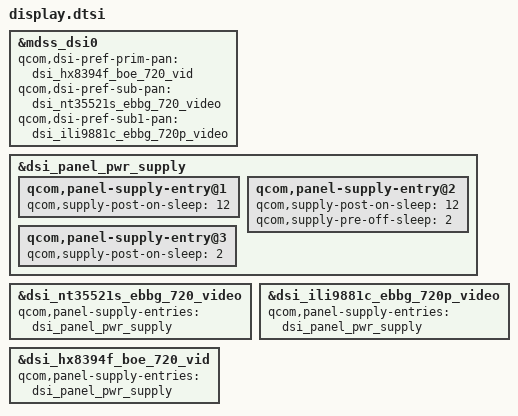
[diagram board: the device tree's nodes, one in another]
#include "panels/dsi-panel-hx8394f-boe-c3a-720p-video.dtsi"
#include "panels/dsi-panel-nt35521s-ebbg-c3a-720p-video.dtsi"
#include "panels/dsi-panel-ili9881c-ebbg-c3a-720p-video.dtsi"

&mdss_dsi0 {
	qcom,dsi-pref-prim-pan = <&dsi_hx8394f_boe_720_vid>;
	qcom,dsi-pref-sub-pan = <&dsi_nt35521s_ebbg_720_video>;
	qcom,dsi-pref-sub1-pan = <&dsi_ili9881c_ebbg_720p_video>;
};

&dsi_panel_pwr_supply {
        qcom,panel-supply-entry@1 {
	        qcom,supply-post-on-sleep = <12>;
	};
	qcom,panel-supply-entry@2 {
		qcom,supply-post-on-sleep = <12>;
		qcom,supply-pre-off-sleep = <2>;
	};
	qcom,panel-supply-entry@3 {
		qcom,supply-post-on-sleep = <2>;
	};
};

&dsi_nt35521s_ebbg_720_video {
	qcom,panel-supply-entries = <&dsi_panel_pwr_supply>;
};
&dsi_ili9881c_ebbg_720p_video {
	qcom,panel-supply-entries = <&dsi_panel_pwr_supply>;
};

&dsi_hx8394f_boe_720_vid {
	qcom,panel-supply-entries = <&dsi_panel_pwr_supply>;
};
